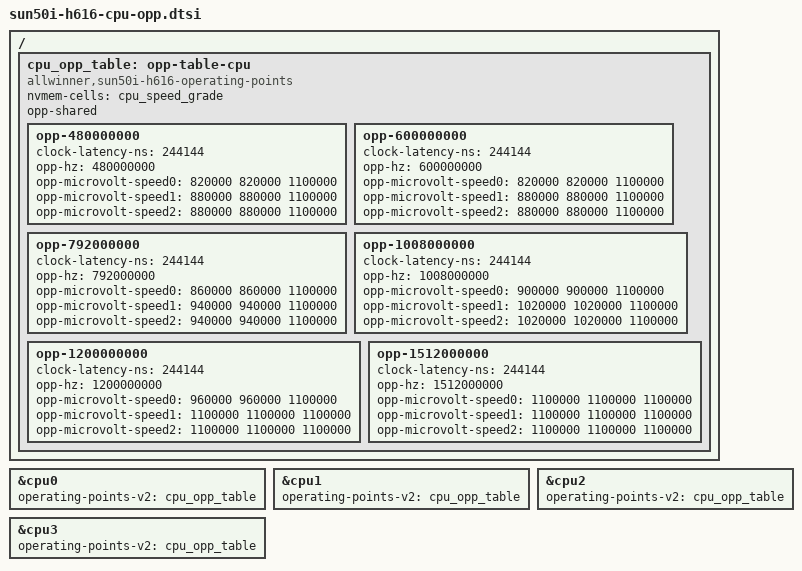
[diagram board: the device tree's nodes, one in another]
//SPDX-License-Identifier: (GPL-2.0+ OR MIT)
//Testing Version 1  from: AGM1968 <AGM1968@users.noreply.github.com>
//Noted: PLL_CPUX = 24 MHz*N/P (WIP)

/ {
	cpu_opp_table: opp-table-cpu {
		compatible = "allwinner,sun50i-h616-operating-points";
		nvmem-cells = <&cpu_speed_grade>;
		opp-shared;

		opp-480000000 {
			clock-latency-ns = <244144>; /* 8 32k periods */
			opp-hz = /bits/ 64 <480000000>;
			opp-microvolt-speed0 = <820000 820000 1100000>; 
			opp-microvolt-speed1 = <880000 880000 1100000>;
			opp-microvolt-speed2 = <880000 880000 1100000>;
		};
	
		opp-600000000 {
			clock-latency-ns = <244144>; /* 8 32k periods */
			opp-hz = /bits/ 64 <600000000>;
			opp-microvolt-speed0 = <820000 820000 1100000>;
			opp-microvolt-speed1 = <880000 880000 1100000>;
			opp-microvolt-speed2 = <880000 880000 1100000>;
		};

		opp-792000000 {
			clock-latency-ns = <244144>; /* 8 32k periods */
			opp-hz = /bits/ 64 <792000000>;
			opp-microvolt-speed0 = <860000 860000 1100000>;
			opp-microvolt-speed1 = <940000 940000 1100000>;
			opp-microvolt-speed2 = <940000 940000 1100000>;
		};

		opp-1008000000 {
			clock-latency-ns = <244144>; /* 8 32k periods */
			opp-hz = /bits/ 64 <1008000000>;
			opp-microvolt-speed0 = <900000 900000 1100000>;
			opp-microvolt-speed1 = <1020000 1020000 1100000>;
			opp-microvolt-speed2 = <1020000 1020000 1100000>;
		};

		opp-1200000000 {
			clock-latency-ns = <244144>; /* 8 32k periods */
			opp-hz = /bits/ 64 <1200000000>;
			opp-microvolt-speed0 = <960000 960000 1100000>;
			opp-microvolt-speed1 = <1100000 1100000 1100000>;
			opp-microvolt-speed2 = <1100000 1100000 1100000>;
		};

		opp-1512000000 {
			clock-latency-ns = <244144>; /* 8 32k periods */
			opp-hz = /bits/ 64 <1512000000>;
			opp-microvolt-speed0 = <1100000 1100000 1100000>;
			opp-microvolt-speed1 = <1100000 1100000 1100000>;
			opp-microvolt-speed2 = <1100000 1100000 1100000>;
		};
	};
};

&cpu0 {
	operating-points-v2 = <&cpu_opp_table>;
};

&cpu1 {
	operating-points-v2 = <&cpu_opp_table>;
};

&cpu2 {
	operating-points-v2 = <&cpu_opp_table>;
};

&cpu3 {
	operating-points-v2 = <&cpu_opp_table>;
};
